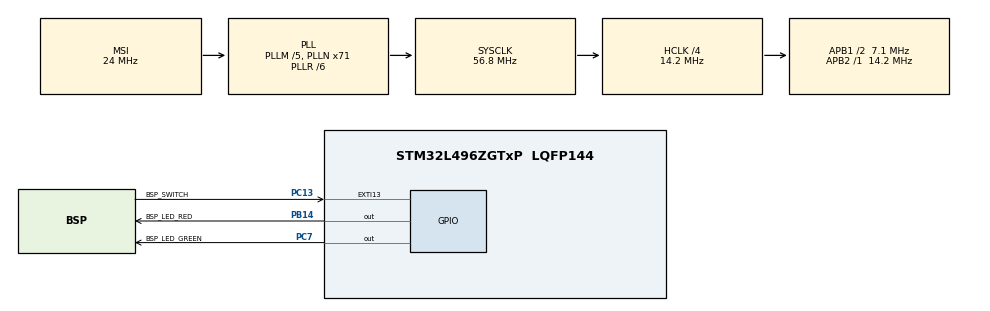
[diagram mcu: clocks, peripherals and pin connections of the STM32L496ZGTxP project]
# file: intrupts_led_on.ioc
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Mcu.Family=STM32L4
Mcu.Name=STM32L496ZGTxP
Mcu.Package=LQFP144
NVIC.EXTI15_10_IRQn=true\:0\:0\:false\:false\:true\:true\:true\:true
NVIC.PriorityGroup=NVIC_PRIORITYGROUP_4
PB14.GPIO_Label=BSP_LED_RED
PB14.Signal=GPIO_Output
PC13.GPIO_Label=BSP_SWITCH
PC13.Signal=GPXTI13
PC7.GPIO_Label=BSP_LED_GREEN
PC7.Signal=GPIO_Output
PH0-OSC_IN\ (PH0).Mode=HSE-External-Oscillator
PH0-OSC_IN\ (PH0).Signal=RCC_OSC_IN
PH1-OSC_OUT\ (PH1).Mode=HSE-External-Oscillator
PH1-OSC_OUT\ (PH1).Signal=RCC_OSC_OUT
ProjectManager.HeapSize=0x200
ProjectManager.StackSize=0x400
ProjectManager.TargetToolchain=STM32CubeIDE
RCC.48MHZClocksFreq_Value=24000000
RCC.ADCFreq_Value=48000000
RCC.AHBCLKDivider=RCC_SYSCLK_DIV4
RCC.AHBFreq_Value=14200000
RCC.APB1CLKDivider=RCC_HCLK_DIV2
RCC.APB1Freq_Value=7100000
RCC.APB1TimFreq_Value=14200000
RCC.APB2Freq_Value=14200000
RCC.APB2TimFreq_Value=14200000
RCC.CortexFreq_Value=14200000
RCC.HCLKFreq_Value=14200000
RCC.HSE_VALUE=8000000
RCC.HSI48_VALUE=48000000
RCC.HSI_VALUE=16000000
RCC.MSIClockRange=RCC_MSIRANGE_9
RCC.MSI_VALUE=24000000
RCC.PLLM=5
RCC.PLLMUL=RCC_PLL_MUL9
RCC.PLLN=71
RCC.PLLR=RCC_PLLR_DIV6
RCC.PLLSAI1N=20
RCC.PRESCALERUSB=RCC_USBCLKSOURCE_PLL_DIV1_5
RCC.SYSCLKFreq_VALUE=56800000
RCC.SYSCLKSource=RCC_SYSCLKSOURCE_PLLCLK
RCC.SYSCLKSourceVirtual=RCC_SYSCLKSOURCE_PLLCLK
RCC.USBFreq_Value=48000000
RCC.VCOOutputFreq_Value=340800000
board=NUCLEO-L496ZG-P

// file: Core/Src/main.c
/* USER CODE BEGIN Header */
/**
  ******************************************************************************
  * @file           : main.c
  * @brief          : Main program body
  ******************************************************************************
  * @attention
  *
  * Copyright (c) 2023 STMicroelectronics.
  * All rights reserved.
  *
  * This software is licensed under terms that can be found in the LICENSE file
  * in the root directory of this software component.
  * If no LICENSE file comes with this software, it is provided AS-IS.
  *
  ******************************************************************************
  */
/* USER CODE END Header */
#include "main.h"

/* USER CODE BEGIN Includes */
#include "stdbool.h"
/* USER CODE END Includes */

/* USER CODE BEGIN PV */
//uint8_t button;
/* USER CODE END PV */

void SystemClock_Config(void);
static void MX_GPIO_Init(void);

/* USER CODE BEGIN 0 */
void HAL_GPIO_EXTI_Callback(uint16_t GPIO_Pin)
{
	if (BSP_SWITCH_Pin == GPIO_Pin)
	{
				static bool flag;
				if (flag == false)
				{
					HAL_GPIO_WritePin(BSP_LED_GREEN_GPIO_Port, BSP_LED_GREEN_Pin,GPIO_PIN_SET);
					HAL_GPIO_WritePin(BSP_LED_RED_GPIO_Port, BSP_LED_RED_Pin,GPIO_PIN_SET);
					flag = true;
				}
				else
				{
				HAL_GPIO_WritePin(BSP_LED_GREEN_GPIO_Port, BSP_LED_GREEN_Pin,GPIO_PIN_RESET);
				HAL_GPIO_WritePin(BSP_LED_RED_GPIO_Port, BSP_LED_RED_Pin,GPIO_PIN_RESET);
				flag = false;
				}
	}

}
/* USER CODE END 0 */

int main(void)
{

  /* MCU Configuration--------------------------------------------------------*/

  /* Reset of all peripherals, Initializes the Flash interface and the Systick. */
  HAL_Init();

  /* Configure the system clock */
  SystemClock_Config();

  /* Initialize all configured peripherals */
  MX_GPIO_Init();

  /* Infinite loop */
  while (1)
  {

  }
}

void SystemClock_Config(void)
{
  RCC_OscInitTypeDef RCC_OscInitStruct = {0};
  RCC_ClkInitTypeDef RCC_ClkInitStruct = {0};

  /** Configure the main internal regulator output voltage
  */
  if (HAL_PWREx_ControlVoltageScaling(PWR_REGULATOR_VOLTAGE_SCALE1) != HAL_OK)
  {
    Error_Handler();
  }

  /** Initializes the RCC Oscillators according to the specified parameters
  * in the RCC_OscInitTypeDef structure.
  */
  RCC_OscInitStruct.OscillatorType = RCC_OSCILLATORTYPE_MSI;
  RCC_OscInitStruct.MSIState = RCC_MSI_ON;
  RCC_OscInitStruct.MSICalibrationValue = 0;
  RCC_OscInitStruct.MSIClockRange = RCC_MSIRANGE_9;
  RCC_OscInitStruct.PLL.PLLState = RCC_PLL_ON;
  RCC_OscInitStruct.PLL.PLLSource = RCC_PLLSOURCE_MSI;
  RCC_OscInitStruct.PLL.PLLM = 5;
  RCC_OscInitStruct.PLL.PLLN = 71;
  RCC_OscInitStruct.PLL.PLLP = RCC_PLLP_DIV2;
  RCC_OscInitStruct.PLL.PLLQ = RCC_PLLQ_DIV2;
  RCC_OscInitStruct.PLL.PLLR = RCC_PLLR_DIV6;
  if (HAL_RCC_OscConfig(&RCC_OscInitStruct) != HAL_OK)
  {
    Error_Handler();
  }

  /** Initializes the CPU, AHB and APB buses clocks
  */
  RCC_ClkInitStruct.ClockType = RCC_CLOCKTYPE_HCLK|RCC_CLOCKTYPE_SYSCLK
                              |RCC_CLOCKTYPE_PCLK1|RCC_CLOCKTYPE_PCLK2;
  RCC_ClkInitStruct.SYSCLKSource = RCC_SYSCLKSOURCE_PLLCLK;
  RCC_ClkInitStruct.AHBCLKDivider = RCC_SYSCLK_DIV4;
  RCC_ClkInitStruct.APB1CLKDivider = RCC_HCLK_DIV2;
  RCC_ClkInitStruct.APB2CLKDivider = RCC_HCLK_DIV1;

  if (HAL_RCC_ClockConfig(&RCC_ClkInitStruct, FLASH_LATENCY_0) != HAL_OK)
  {
    Error_Handler();
  }
}

static void MX_GPIO_Init(void)
{
  GPIO_InitTypeDef GPIO_InitStruct = {0};

  /* GPIO Ports Clock Enable */
  __HAL_RCC_GPIOC_CLK_ENABLE();
  __HAL_RCC_GPIOH_CLK_ENABLE();
  __HAL_RCC_GPIOB_CLK_ENABLE();

  /*Configure GPIO pin Output Level */
  HAL_GPIO_WritePin(BSP_LED_RED_GPIO_Port, BSP_LED_RED_Pin, GPIO_PIN_RESET);

  /*Configure GPIO pin Output Level */
  HAL_GPIO_WritePin(BSP_LED_GREEN_GPIO_Port, BSP_LED_GREEN_Pin, GPIO_PIN_RESET);

  /*Configure GPIO pin : BSP_SWITCH_Pin */
  GPIO_InitStruct.Pin = BSP_SWITCH_Pin;
  GPIO_InitStruct.Mode = GPIO_MODE_IT_RISING;
  GPIO_InitStruct.Pull = GPIO_NOPULL;
  HAL_GPIO_Init(BSP_SWITCH_GPIO_Port, &GPIO_InitStruct);

  /*Configure GPIO pin : BSP_LED_RED_Pin */
  GPIO_InitStruct.Pin = BSP_LED_RED_Pin;
  GPIO_InitStruct.Mode = GPIO_MODE_OUTPUT_PP;
  GPIO_InitStruct.Pull = GPIO_NOPULL;
  GPIO_InitStruct.Speed = GPIO_SPEED_FREQ_LOW;
  HAL_GPIO_Init(BSP_LED_RED_GPIO_Port, &GPIO_InitStruct);

  /*Configure GPIO pin : BSP_LED_GREEN_Pin */
  GPIO_InitStruct.Pin = BSP_LED_GREEN_Pin;
  GPIO_InitStruct.Mode = GPIO_MODE_OUTPUT_PP;
  GPIO_InitStruct.Pull = GPIO_NOPULL;
  GPIO_InitStruct.Speed = GPIO_SPEED_FREQ_LOW;
  HAL_GPIO_Init(BSP_LED_GREEN_GPIO_Port, &GPIO_InitStruct);

  /* EXTI interrupt init*/
  HAL_NVIC_SetPriority(EXTI15_10_IRQn, 0, 0);
  HAL_NVIC_EnableIRQ(EXTI15_10_IRQn);

}

/* USER CODE BEGIN 4 */
//  void HAL_GPIO_EXTI_Callback(uint16_t GPIO_Pin)
//  {
//	if (BSP_SWITCH_Pin == GPIO_Pin)
//	{
//				static bool flag;
//				if (flag == false)
//				{
//					HAL_GPIO_WritePin(BSP_LED_GREEN_GPIO_Port, BSP_LED_GREEN_Pin,GPIO_PIN_SET);
//					HAL_GPIO_WritePin(BSP_LED_RED_GPIO_Port, BSP_LED_RED_Pin,GPIO_PIN_SET);
//					flag = true;
//				}
//				else
//				{
//				HAL_GPIO_WritePin(BSP_LED_GREEN_GPIO_Port, BSP_LED_GREEN_Pin,GPIO_PIN_RESET);
//				HAL_GPIO_WritePin(BSP_LED_RED_GPIO_Port, BSP_LED_RED_Pin,GPIO_PIN_RESET);
//				flag = false;
//				}
//	}
//
//}
/* USER CODE END 4 */

void Error_Handler(void)
{
  __disable_irq();
  while (1)
  {
  }
}
